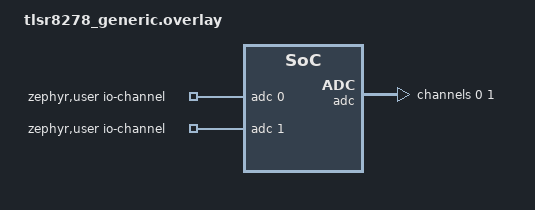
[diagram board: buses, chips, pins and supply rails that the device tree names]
/*
 * SPDX-License-Identifier: Apache-2.0
 */

#include <zephyr/dt-bindings/adc/adc.h>

/ {
	zephyr,user {
		io-channels = <&adc 0>, <&adc 1>;
	};
};

&adc {
	#address-cells = <1>;
	#size-cells = <0>;

	channel@0 {
		reg = <0>;
		zephyr,gain = "ADC_GAIN_1";
		zephyr,reference = "ADC_REF_INTERNAL";
		zephyr,acquisition-time = <ADC_ACQ_TIME_DEFAULT>;
		zephyr,resolution = <13>;
		zephyr,input-positive = <4>;
	};

	channel@1 {
		reg = <1>;
		zephyr,gain = "ADC_GAIN_1";
		zephyr,reference = "ADC_REF_INTERNAL";
		zephyr,acquisition-time = <ADC_ACQ_TIME_DEFAULT>;
		zephyr,resolution = <13>;
		zephyr,input-positive = <9>;
	};
};
